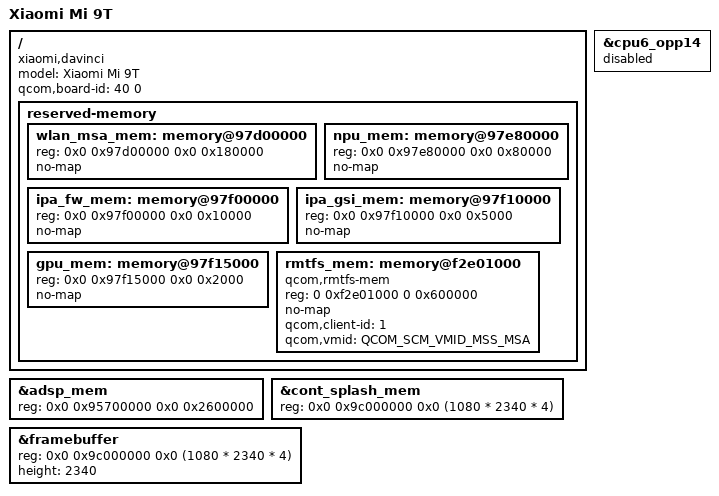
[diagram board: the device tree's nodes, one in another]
// SPDX-License-Identifier: BSD-3-Clause
/*
 * Xiaomi Mi 9T (davinci) board device tree source
 *
 * (C) Copyright 2024 Danila Tikhonov <danila@jiaxyga.com>
 */

 /dts-v1/;

 #include "sm7150-xiaomi-common.dtsi"

 /delete-node/ &wlan_msa_mem;
 /delete-node/ &npu_mem;
 /delete-node/ &ipa_fw_mem;
 /delete-node/ &ipa_gsi_mem;
 /delete-node/ &gpu_mem;

 &adsp_mem {
	reg = <0x0 0x95700000 0x0 0x2600000>;
 };

 &cont_splash_mem {
	reg = <0x0 0x9c000000 0x0 (1080 * 2340 * 4)>;
 };

 /*
  * Davinci uses the SM7150-AA SoC.
  * Limit CPU clock to 2.2 GHz
  */

 &cpu6_opp14 {
	status = "disabled";
 };

 / {
	/*
	 * Xiaomi Mi 9T
	 * Xiaomi Redmi K20
	 */
	model = "Xiaomi Mi 9T";
	compatible = "xiaomi,davinci", "qcom,sm7150";

	qcom,board-id = <40 0>;

	reserved-memory {
		wlan_msa_mem: memory@97d00000 {
			reg = <0x0 0x97d00000 0x0 0x180000>;
			no-map;
		};

		npu_mem: memory@97e80000 {
			reg = <0x0 0x97e80000 0x0 0x80000>;
			no-map;
		};

		ipa_fw_mem: memory@97f00000 {
			reg = <0x0 0x97f00000 0x0 0x10000>;
			no-map;
		};

		ipa_gsi_mem: memory@97f10000 {
			reg = <0x0 0x97f10000 0x0 0x5000>;
			no-map;
		};

		gpu_mem: memory@97f15000 {
			reg = <0x0 0x97f15000 0x0 0x2000>;
			no-map;
		};

		rmtfs_mem: memory@f2e01000 {
			compatible = "qcom,rmtfs-mem";
			reg = <0 0xf2e01000 0 0x600000>;
			no-map;

			qcom,client-id = <1>;
			qcom,vmid = <QCOM_SCM_VMID_MSS_MSA>;
		};
	};
};

 &framebuffer {
	reg = <0x0 0x9c000000 0x0 (1080 * 2340 * 4)>;
	height = <2340>;
};
